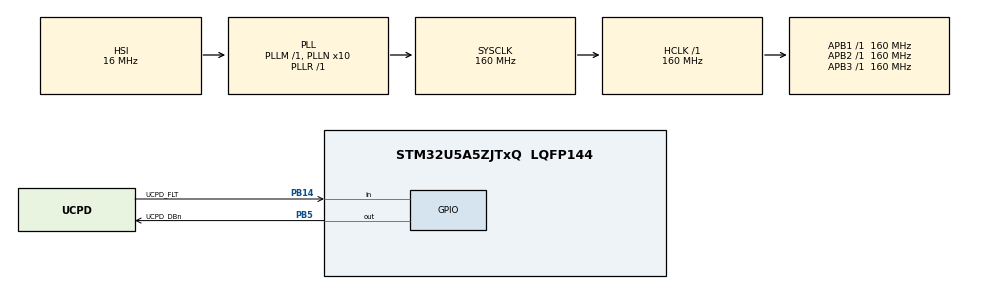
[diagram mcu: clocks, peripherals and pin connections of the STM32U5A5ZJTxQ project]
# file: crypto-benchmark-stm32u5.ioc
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CORTEX_M33_NS.userName=CORTEX_M33
Mcu.Family=STM32U5
Mcu.Name=STM32U5A5ZJTxQ
Mcu.Package=LQFP144
NUCLEO-U5A5ZJ-Q.BUTTON=1
NUCLEO-U5A5ZJ-Q.Bsp_Common_DEMO=true
NUCLEO-U5A5ZJ-Q.LD1=true
NUCLEO-U5A5ZJ-Q.LD2=true
NUCLEO-U5A5ZJ-Q.LD3=true
NUCLEO-U5A5ZJ-Q.VCP=true
NVIC.EXTI13_IRQn=true\:0\:0\:false\:false\:true\:false\:true\:true
NVIC.PriorityGroup=NVIC_PRIORITYGROUP_4
PA10.Signal=USART1_RX
PA11.Signal=USB_OTG_HS_DM
PA12.Signal=USB_OTG_HS_DP
PA13\ (JTMS/SWDIO).Mode=Trace_Asynchronous_SW
PA13\ (JTMS/SWDIO).Signal=DEBUG_JTMS-SWDIO
PA14\ (JTCK/SWCLK).Mode=Trace_Asynchronous_SW
PA14\ (JTCK/SWCLK).Signal=DEBUG_JTCK-SWCLK
PA15\ (JTDI).Signal=UCPD1_CC1
PA9.Signal=USART1_TX
PB14.GPIO_Label=UCPD_FLT
PB14.Signal=GPIO_Input
PB15.Signal=UCPD1_CC2
PB3\ (JTDO/TRACESWO).Mode=Trace_Asynchronous_SW
PB3\ (JTDO/TRACESWO).Signal=DEBUG_JTDO-SWO
PB5.GPIO_Label=UCPD_DBn
PB5.Signal=GPIO_Output
PC14-OSC32_IN\ (PC14).Mode=LSE-External-Oscillator
PC14-OSC32_IN\ (PC14).Signal=RCC_OSC32_IN
PC15-OSC32_OUT\ (PC15).Mode=LSE-External-Oscillator
PC15-OSC32_OUT\ (PC15).Signal=RCC_OSC32_OUT
PC2.GPIO_Label=VBUS_SENSE
PC2.Signal=ADC1_IN3
PH0-OSC_IN\ (PH0).Mode=HSE-External-Clock-Source
PH0-OSC_IN\ (PH0).Signal=RCC_OSC_IN
PH1-OSC_OUT\ (PH1).Signal=RCC_OSC_OUT
PWR.PowerMode=PWR_SMPS_SUPPLY
ProjectManager.HeapSize=0x2000
ProjectManager.StackSize=0x40000
ProjectManager.TargetToolchain=Makefile
RCC.ADCFreq_Value=16000000
RCC.AHBFreq_Value=160000000
RCC.APB1Freq_Value=160000000
RCC.APB1TimFreq_Value=160000000
RCC.APB2Freq_Value=160000000
RCC.APB2TimFreq_Value=160000000
RCC.APB3Freq_Value=160000000
RCC.CortexFreq_Value=160000000
RCC.DACCLockSelectionVirtual=RCC_DAC1CLKSOURCE_LSI
RCC.EPOD_VALUE=16000000
RCC.HCLKFreq_Value=160000000
RCC.HSE_VALUE=8000000
RCC.HSI48_VALUE=48000000
RCC.HSI_VALUE=16000000
RCC.LSIDIV_VALUE=32000
RCC.MSIClockRange=RCC_MSIRANGE_1
RCC.MSI_VALUE=24000000
RCC.PLL1P=8
RCC.PLL1R=1
RCC.PLLFRACN=0
RCC.PLLN=10
RCC.PLLSourceVirtual=RCC_PLLSOURCE_HSI
RCC.SYSCLKFreq_VALUE=160000000
RCC.SYSCLKSource=RCC_SYSCLKSOURCE_PLLCLK
RCC.VCOOutputFreq_Value=160000000
VP_DCACHE1_VS_DCACHE.Mode=DCACHE_Activate
VP_ICACHE_VS_ICACHE.Mode=DirectMappedCache
VP_LPBAMQUEUE_VS_QUEUE.Mode=QUEUEMODE
VP_MEMORYMAP_VS_MEMORYMAP.Mode=CurAppReg
VP_NUCLEO-U5A5ZJ-Q_VS_BSP_COMMON.Mode=COMMON
VP_PWR_VS_DBSignals.Mode=DisableDeadBatterySignals
VP_PWR_VS_LPOM.Mode=PowerOptimisation
VP_PWR_VS_SECSignals.Mode=Security/Privilege
board=NUCLEO-U5A5ZJ-Q

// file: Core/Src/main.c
/* USER CODE BEGIN Header */
/**
  ******************************************************************************
  * @file           : main.c
  * @brief          : Main program body
  ******************************************************************************
  * @attention
  *
  * Copyright (c) 2026 STMicroelectronics.
  * All rights reserved.
  *
  * This software is licensed under terms that can be found in the LICENSE file
  * in the root directory of this software component.
  * If no LICENSE file comes with this software, it is provided AS-IS.
  *
  ******************************************************************************
  */
/* USER CODE END Header */
#include "main.h"

COM_InitTypeDef BspCOMInit;
__IO uint32_t BspButtonState = BUTTON_RELEASED;

DCACHE_HandleTypeDef hdcache1;

void SystemClock_Config(void);
static void SystemPower_Config(void);
static void MX_GPIO_Init(void);
static void MX_ICACHE_Init(void);
static void MX_DCACHE1_Init(void);

/* USER CODE BEGIN 0 */
//****************************************************************************

volatile unsigned int *DWT_CYCCNT   = (volatile unsigned int *)0xE0001004;
volatile unsigned int *DWT_CONTROL  = (volatile unsigned int *)0xE0001000;
volatile unsigned int *DWT_LAR      = (volatile unsigned int *)0xE0001FB0;
volatile unsigned int *SCB_DHCSR    = (volatile unsigned int *)0xE000EDF0;
volatile unsigned int *SCB_DEMCR    = (volatile unsigned int *)0xE000EDFC;
volatile unsigned int *ITM_TER      = (volatile unsigned int *)0xE0000E00;
volatile unsigned int *ITM_TCR      = (volatile unsigned int *)0xE0000E80;

volatile unsigned int *DWT_COMP0   = (volatile unsigned int *)0xE0001020;
volatile unsigned int *DWT_MASK0   = (volatile unsigned int *)0xE0001024;
volatile unsigned int *DWT_FUNC0   = (volatile unsigned int *)0xE0001028;
#define DWT_FUNC0_CYCMATCH 			(1<<7)
#define DWT_FUNC0_GEN_WATCHPOINT 	4
//****************************************************************************

static int Debug_ITMDebug = 0;

//****************************************************************************
volatile uint32_t dwt_comp = 15444020;//15444036
void EnableTiming(void){
  if ((*SCB_DHCSR & 1) && (*ITM_TER & 1)) // Enabled?
    Debug_ITMDebug = 1;

  *SCB_DEMCR |= 0x01000000;
  *DWT_LAR = 0xC5ACCE55; // enable access
  *DWT_CYCCNT = 0; // reset the counter

  //setup break point based on clock cycles
  *DWT_COMP0 = dwt_comp;
  *DWT_MASK0 = 0;
  //*DWT_FUNC0 = DWT_FUNC0_CYCMATCH | DWT_FUNC0_GEN_WATCHPOINT;

  *DWT_CONTROL |= 1 ; // enable the counter
}

uint32_t LBMK_get_cpu_timestamp(){
	return *DWT_CYCCNT;
}

void com_tx(const void *const buf, unsigned int size){
	HAL_UART_Transmit(&hcom_uart[COM1], (const uint8_t*)buf, size, 0xFFFF);
}
void com_rx(void *const buf, unsigned int size){
	HAL_UART_Receive(&hcom_uart[COM1], (uint8_t*)buf, size, 0xFFFF);
}
#include <stdio.h>
#include <stdbool.h>

int LBMK_putchar(int ch);
int __io_putchar(int ch){
	return LBMK_putchar(ch);
}

void LBMK_clear_caches(){
  __HAL_FLASH_PREFETCH_BUFFER_DISABLE();
	HAL_ICACHE_Invalidate();
	HAL_ICACHE_WaitForInvalidateComplete();
	HAL_DCACHE_Invalidate(&hdcache1);
	__HAL_FLASH_PREFETCH_BUFFER_ENABLE();
}

void LBMK_init_leancom();
void lean_benchmark(unsigned int ninfo, const char*info[], bool run_forever);
int icache_enabled=0;
int dcache_enabled=0;

typedef uint32_t cmox_init_retval_t;
/* value of CMOX_INIT_SUCCESS in cmox_common.h of the STM32 Cryptographic middleware V5 (X-CUBE-CRYPTOLIB); it was 0 in
   the packages before V5. The library checks the return value of cmox_ll_init() against it. */
#define CMOX_INIT_SUCCESS       ((cmox_init_retval_t)0x5ba93f71) /*!< Init operation successfully performed */

#include "stm32u5xx_hal.h"
/**
  * @brief          CMOX library low level initialization
  * @param          pArg User defined parameter that is transmitted from initialize service
  * @retval         Initialization status: @ref CMOX_INIT_SUCCESS / @ref CMOX_INIT_FAIL
  */
cmox_init_retval_t cmox_ll_init(void *pArg)
{
  (void)pArg;
  /* Ensure CRC is enabled for cryptographic processing */
  __HAL_RCC_CRC_RELEASE_RESET();
  __HAL_RCC_CRC_CLK_ENABLE();
  return CMOX_INIT_SUCCESS;
}

/**
  * @brief          CMOX library low level de-initialization
  * @param          pArg User defined parameter that is transmitted from finalize service
  * @retval         De-initialization status: @ref CMOX_INIT_SUCCESS / @ref CMOX_INIT_FAIL
  */
cmox_init_retval_t cmox_ll_deInit(void *pArg)
{
  (void)pArg;
  /* Do not turn off CRC to avoid side effect on other SW parts using it */
  return CMOX_INIT_SUCCESS;
}
/* USER CODE END 0 */

int main(void)
{

  /* MCU Configuration--------------------------------------------------------*/

  /* Reset of all peripherals, Initializes the Flash interface and the Systick. */
  HAL_Init();

  /* Configure the System Power */
  SystemPower_Config();

  /* Configure the system clock */
  SystemClock_Config();

  /* Initialize all configured peripherals */
  MX_GPIO_Init();
  MX_ICACHE_Init();
  MX_DCACHE1_Init();

  /* Initialize leds */
  BSP_LED_Init(LED_GREEN);
  BSP_LED_Init(LED_BLUE);
  BSP_LED_Init(LED_RED);

  /* Initialize USER push-button, will be used to trigger an interrupt each time it's pressed.*/
  BSP_PB_Init(BUTTON_USER, BUTTON_MODE_EXTI);

  /* Initialize COM1 port (115200, 8 bits (7-bit data + 1 stop bit), no parity */
  BspCOMInit.BaudRate   = 115200;
  BspCOMInit.WordLength = COM_WORDLENGTH_8B;
  BspCOMInit.StopBits   = COM_STOPBITS_1;
  BspCOMInit.Parity     = COM_PARITY_NONE;
  BspCOMInit.HwFlowCtl  = COM_HWCONTROL_NONE;
  if (BSP_COM_Init(COM1, &BspCOMInit) != BSP_ERROR_NONE)
  {
    Error_Handler();
  }

  /* USER CODE BEGIN BSP */
  BSP_LED_On(LED_GREEN);
  LBMK_init_leancom();
  BSP_LED_On(LED_BLUE);
  printf("crypto-benchmark-stm32u5\r\n");
  const uint32_t sys_clk = HAL_RCC_GetSysClockFreq();
  printf("SYS clock frequency = %lu MHz\r\n",sys_clk/1000000);
  char frequency_mhz[10] = {0};
  sprintf(frequency_mhz,"%lu",sys_clk/1000000);
  EnableTiming();
  const char* icache_str = icache_enabled ? "enabled" : "disabled";
  const char* dcache_str = dcache_enabled ? "enabled" : "disabled";
	const char*hw_info[] = {
	  "hw_platform", "stm32u5",
	  "frequency_mhz", frequency_mhz,
	  "ICACHE", icache_str,
	  "DCACHE", dcache_str
	};
  lean_benchmark(sizeof(hw_info)/sizeof(char*),hw_info,0);

  BSP_LED_On(LED_RED);
  /* USER CODE END BSP */

  /* Infinite loop */
  /* USER CODE BEGIN WHILE */
  while (1)
  {

    /* -- Sample board code for User push-button in interrupt mode ---- */
    if (BspButtonState == BUTTON_PRESSED)
    {
      /* Update button state */
      BspButtonState = BUTTON_RELEASED;
      /* -- Sample board code to toggle leds ---- */
      BSP_LED_Toggle(LED_GREEN);
      BSP_LED_Toggle(LED_BLUE);
      BSP_LED_Toggle(LED_RED);
      /* ..... Perform your action ..... */
    }
    /* USER CODE END WHILE */

  }
}

void SystemClock_Config(void)
{
  RCC_OscInitTypeDef RCC_OscInitStruct = {0};
  RCC_ClkInitTypeDef RCC_ClkInitStruct = {0};

  /** Configure the main internal regulator output voltage
  */
  if (HAL_PWREx_ControlVoltageScaling(PWR_REGULATOR_VOLTAGE_SCALE1) != HAL_OK)
  {
    Error_Handler();
  }

  /** Initializes the CPU, AHB and APB buses clocks
  */
  RCC_OscInitStruct.OscillatorType = RCC_OSCILLATORTYPE_HSI;
  RCC_OscInitStruct.HSIState = RCC_HSI_ON;
  RCC_OscInitStruct.HSICalibrationValue = RCC_HSICALIBRATION_DEFAULT;
  RCC_OscInitStruct.PLL.PLLState = RCC_PLL_ON;
  RCC_OscInitStruct.PLL.PLLSource = RCC_PLLSOURCE_HSI;
  RCC_OscInitStruct.PLL.PLLMBOOST = RCC_PLLMBOOST_DIV1;
  RCC_OscInitStruct.PLL.PLLM = 1;
  RCC_OscInitStruct.PLL.PLLN = 10;
  RCC_OscInitStruct.PLL.PLLP = 8;
  RCC_OscInitStruct.PLL.PLLQ = 2;
  RCC_OscInitStruct.PLL.PLLR = 1;
  RCC_OscInitStruct.PLL.PLLRGE = RCC_PLLVCIRANGE_1;
  RCC_OscInitStruct.PLL.PLLFRACN = 0;
  if (HAL_RCC_OscConfig(&RCC_OscInitStruct) != HAL_OK)
  {
    Error_Handler();
  }

  /** Initializes the CPU, AHB and APB buses clocks
  */
  RCC_ClkInitStruct.ClockType = RCC_CLOCKTYPE_HCLK|RCC_CLOCKTYPE_SYSCLK
                              |RCC_CLOCKTYPE_PCLK1|RCC_CLOCKTYPE_PCLK2
                              |RCC_CLOCKTYPE_PCLK3;
  RCC_ClkInitStruct.SYSCLKSource = RCC_SYSCLKSOURCE_PLLCLK;
  RCC_ClkInitStruct.AHBCLKDivider = RCC_SYSCLK_DIV1;
  RCC_ClkInitStruct.APB1CLKDivider = RCC_HCLK_DIV1;
  RCC_ClkInitStruct.APB2CLKDivider = RCC_HCLK_DIV1;
  RCC_ClkInitStruct.APB3CLKDivider = RCC_HCLK_DIV1;

  if (HAL_RCC_ClockConfig(&RCC_ClkInitStruct, FLASH_LATENCY_4) != HAL_OK)
  {
    Error_Handler();
  }
}

/**
  * @brief Power Configuration
  * @retval None
  */
static void SystemPower_Config(void)
{

  /*
   * Disable the internal Pull-Up in Dead Battery pins of UCPD peripheral
   */
  HAL_PWREx_DisableUCPDDeadBattery();

  /*
   * Switch to SMPS regulator instead of LDO
   */
  if (HAL_PWREx_ConfigSupply(PWR_SMPS_SUPPLY) != HAL_OK)
  {
    Error_Handler();
  }
}

static void MX_DCACHE1_Init(void)
{

  hdcache1.Instance = DCACHE1;
  hdcache1.Init.ReadBurstType = DCACHE_READ_BURST_WRAP;
  if (HAL_DCACHE_Init(&hdcache1) != HAL_OK)
  {
    Error_Handler();
  }
  /* USER CODE BEGIN DCACHE1_Init 2 */
  dcache_enabled=1;
  /* USER CODE END DCACHE1_Init 2 */

}

static void MX_ICACHE_Init(void)
{

  /** Enable instruction cache in 1-way (direct mapped cache)
  */
  if (HAL_ICACHE_ConfigAssociativityMode(ICACHE_1WAY) != HAL_OK)
  {
    Error_Handler();
  }
  if (HAL_ICACHE_Enable() != HAL_OK)
  {
    Error_Handler();
  }
  /* USER CODE BEGIN ICACHE_Init 2 */
  icache_enabled=1;
  /* USER CODE END ICACHE_Init 2 */

}

static void MX_GPIO_Init(void)
{
  GPIO_InitTypeDef GPIO_InitStruct = {0};

  /* GPIO Ports Clock Enable */
  __HAL_RCC_GPIOC_CLK_ENABLE();
  __HAL_RCC_GPIOH_CLK_ENABLE();
  __HAL_RCC_GPIOB_CLK_ENABLE();
  __HAL_RCC_GPIOA_CLK_ENABLE();

  /*Configure GPIO pin Output Level */
  HAL_GPIO_WritePin(UCPD_DBn_GPIO_Port, UCPD_DBn_Pin, GPIO_PIN_RESET);

  /*Configure GPIO pin : VBUS_SENSE_Pin */
  GPIO_InitStruct.Pin = VBUS_SENSE_Pin;
  GPIO_InitStruct.Mode = GPIO_MODE_ANALOG;
  GPIO_InitStruct.Pull = GPIO_NOPULL;
  HAL_GPIO_Init(VBUS_SENSE_GPIO_Port, &GPIO_InitStruct);

  /*Configure GPIO pin : UCPD_FLT_Pin */
  GPIO_InitStruct.Pin = UCPD_FLT_Pin;
  GPIO_InitStruct.Mode = GPIO_MODE_INPUT;
  GPIO_InitStruct.Pull = GPIO_NOPULL;
  HAL_GPIO_Init(UCPD_FLT_GPIO_Port, &GPIO_InitStruct);

  /*Configure GPIO pin : PB15 */
  GPIO_InitStruct.Pin = GPIO_PIN_15;
  GPIO_InitStruct.Mode = GPIO_MODE_ANALOG;
  GPIO_InitStruct.Pull = GPIO_NOPULL;
  HAL_GPIO_Init(GPIOB, &GPIO_InitStruct);

  /*Configure GPIO pins : PA11 PA12 */
  GPIO_InitStruct.Pin = GPIO_PIN_11|GPIO_PIN_12;
  GPIO_InitStruct.Mode = GPIO_MODE_AF_PP;
  GPIO_InitStruct.Pull = GPIO_NOPULL;
  GPIO_InitStruct.Speed = GPIO_SPEED_FREQ_LOW;
  HAL_GPIO_Init(GPIOA, &GPIO_InitStruct);

  /*Configure GPIO pin : PA15 */
  GPIO_InitStruct.Pin = GPIO_PIN_15;
  GPIO_InitStruct.Mode = GPIO_MODE_ANALOG;
  GPIO_InitStruct.Pull = GPIO_NOPULL;
  HAL_GPIO_Init(GPIOA, &GPIO_InitStruct);

  /*Configure GPIO pin : UCPD_DBn_Pin */
  GPIO_InitStruct.Pin = UCPD_DBn_Pin;
  GPIO_InitStruct.Mode = GPIO_MODE_OUTPUT_PP;
  GPIO_InitStruct.Pull = GPIO_NOPULL;
  GPIO_InitStruct.Speed = GPIO_SPEED_FREQ_LOW;
  HAL_GPIO_Init(UCPD_DBn_GPIO_Port, &GPIO_InitStruct);

}

/**
  * @brief  BSP Push Button callback
  * @param  Button Specifies the pressed button
  * @retval None
  */
void BSP_PB_Callback(Button_TypeDef Button)
{
  if (Button == BUTTON_USER)
  {
    BspButtonState = BUTTON_PRESSED;
  }
}

void Error_Handler(void)
{
  /* USER CODE BEGIN Error_Handler_Debug */
  /* User can add his own implementation to report the HAL error return state */
  __disable_irq();
  printf("\n\r\nError_Handler\n\r\n");
  while (1)
  {
  }
  /* USER CODE END Error_Handler_Debug */
}
